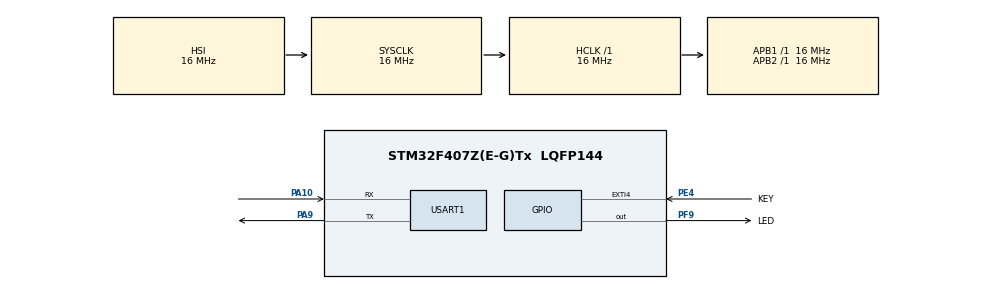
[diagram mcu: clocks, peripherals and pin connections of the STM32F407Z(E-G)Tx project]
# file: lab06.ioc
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Mcu.Family=STM32F4
Mcu.Name=STM32F407Z(E-G)Tx
Mcu.Package=LQFP144
NVIC.EXTI4_IRQn=true\:0\:0\:false\:true\:true\:2\:true\:true
NVIC.PriorityGroup=NVIC_PRIORITYGROUP_4
NVIC.USART1_IRQn=true\:0\:0\:false\:true\:true\:1\:true\:true
PA10.Mode=Asynchronous
PA10.Signal=USART1_RX
PA9.Mode=Asynchronous
PA9.Signal=USART1_TX
PE4.GPIO_Label=KEY
PE4.GPIO_ModeDefaultEXTI=GPIO_MODE_IT_FALLING
PE4.GPIO_PuPd=GPIO_PULLUP
PE4.Signal=GPXTI4
PF9.GPIO_Label=LED
PF9.Signal=GPIO_Output
ProjectManager.HeapSize=0x200
ProjectManager.StackSize=0x400
ProjectManager.TargetToolchain=STM32CubeIDE
RCC.AHBFreq_Value=16000000
RCC.APB1Freq_Value=16000000
RCC.APB2Freq_Value=16000000
RCC.CortexFreq_Value=16000000
RCC.HSE_VALUE=25000000
RCC.HSI_VALUE=16000000
RCC.LSE_VALUE=32768
RCC.SYSCLKFreq_VALUE=16000000
RCC.VCOOutputFreq_Value=192000000
USART1.VirtualMode=VM_ASYNC
board=custom

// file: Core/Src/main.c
/* USER CODE BEGIN Header */
/**
  ******************************************************************************
  * @file           : main.c
  * @brief          : Main program body
  ******************************************************************************
  * @attention
  *
  * <h2><center>&copy; Copyright (c) 2022 STMicroelectronics.
  * All rights reserved.</center></h2>
  *
  * This software component is licensed by ST under BSD 3-Clause license,
  * the "License"; You may not use this file except in compliance with the
  * License. You may obtain a copy of the License at:
  *                        opensource.org/licenses/BSD-3-Clause
  *
  ******************************************************************************
  */
/* USER CODE END Header */
#include "main.h"

/* USER CODE BEGIN Includes */
#include <stdio.h>
/* USER CODE END Includes */

UART_HandleTypeDef huart1;

/* USER CODE BEGIN PV */
char buffer[36];
uint32_t counter;
/* USER CODE END PV */

void SystemClock_Config(void);
static void MX_GPIO_Init(void);
static void MX_USART1_UART_Init(void);
static void MX_NVIC_Init(void);

int main(void)
{

  /* MCU Configuration--------------------------------------------------------*/

  /* Reset of all peripherals, Initializes the Flash interface and the Systick. */
  HAL_Init();

  /* Configure the system clock */
  SystemClock_Config();

  /* Initialize all configured peripherals */
  MX_GPIO_Init();
  MX_USART1_UART_Init();

  /* Initialize interrupts */
  MX_NVIC_Init();

  /* Infinite loop */
  /* USER CODE BEGIN WHILE */
  while (1)
  {
	  sprintf(buffer, "Hello Embedded! Counter: %lu\n\r", counter);
	  HAL_UART_Transmit_IT(&huart1, (uint8_t*)buffer, sizeof(buffer));
	  counter++;
	  HAL_Delay(500);
    /* USER CODE END WHILE */

  }
}

void SystemClock_Config(void)
{
  RCC_OscInitTypeDef RCC_OscInitStruct = {0};
  RCC_ClkInitTypeDef RCC_ClkInitStruct = {0};

  /** Configure the main internal regulator output voltage
  */
  __HAL_RCC_PWR_CLK_ENABLE();
  __HAL_PWR_VOLTAGESCALING_CONFIG(PWR_REGULATOR_VOLTAGE_SCALE1);
  /** Initializes the RCC Oscillators according to the specified parameters
  * in the RCC_OscInitTypeDef structure.
  */
  RCC_OscInitStruct.OscillatorType = RCC_OSCILLATORTYPE_HSI;
  RCC_OscInitStruct.HSIState = RCC_HSI_ON;
  RCC_OscInitStruct.HSICalibrationValue = RCC_HSICALIBRATION_DEFAULT;
  RCC_OscInitStruct.PLL.PLLState = RCC_PLL_NONE;
  if (HAL_RCC_OscConfig(&RCC_OscInitStruct) != HAL_OK)
  {
    Error_Handler();
  }
  /** Initializes the CPU, AHB and APB buses clocks
  */
  RCC_ClkInitStruct.ClockType = RCC_CLOCKTYPE_HCLK|RCC_CLOCKTYPE_SYSCLK
                              |RCC_CLOCKTYPE_PCLK1|RCC_CLOCKTYPE_PCLK2;
  RCC_ClkInitStruct.SYSCLKSource = RCC_SYSCLKSOURCE_HSI;
  RCC_ClkInitStruct.AHBCLKDivider = RCC_SYSCLK_DIV1;
  RCC_ClkInitStruct.APB1CLKDivider = RCC_HCLK_DIV1;
  RCC_ClkInitStruct.APB2CLKDivider = RCC_HCLK_DIV1;

  if (HAL_RCC_ClockConfig(&RCC_ClkInitStruct, FLASH_LATENCY_0) != HAL_OK)
  {
    Error_Handler();
  }
}

/**
  * @brief NVIC Configuration.
  * @retval None
  */
static void MX_NVIC_Init(void)
{
  /* USART1_IRQn interrupt configuration */
  HAL_NVIC_SetPriority(USART1_IRQn, 0, 0);
  HAL_NVIC_EnableIRQ(USART1_IRQn);
  /* EXTI4_IRQn interrupt configuration */
  HAL_NVIC_SetPriority(EXTI4_IRQn, 0, 0);
  HAL_NVIC_EnableIRQ(EXTI4_IRQn);
}

static void MX_USART1_UART_Init(void)
{

  huart1.Instance = USART1;
  huart1.Init.BaudRate = 115200;
  huart1.Init.WordLength = UART_WORDLENGTH_8B;
  huart1.Init.StopBits = UART_STOPBITS_1;
  huart1.Init.Parity = UART_PARITY_NONE;
  huart1.Init.Mode = UART_MODE_TX_RX;
  huart1.Init.HwFlowCtl = UART_HWCONTROL_NONE;
  huart1.Init.OverSampling = UART_OVERSAMPLING_16;
  if (HAL_UART_Init(&huart1) != HAL_OK)
  {
    Error_Handler();
  }

}

static void MX_GPIO_Init(void)
{
  GPIO_InitTypeDef GPIO_InitStruct = {0};

  /* GPIO Ports Clock Enable */
  __HAL_RCC_GPIOE_CLK_ENABLE();
  __HAL_RCC_GPIOF_CLK_ENABLE();
  __HAL_RCC_GPIOA_CLK_ENABLE();

  /*Configure GPIO pin Output Level */
  HAL_GPIO_WritePin(LED_GPIO_Port, LED_Pin, GPIO_PIN_RESET);

  /*Configure GPIO pin : KEY_Pin */
  GPIO_InitStruct.Pin = KEY_Pin;
  GPIO_InitStruct.Mode = GPIO_MODE_IT_FALLING;
  GPIO_InitStruct.Pull = GPIO_PULLUP;
  HAL_GPIO_Init(KEY_GPIO_Port, &GPIO_InitStruct);

  /*Configure GPIO pin : LED_Pin */
  GPIO_InitStruct.Pin = LED_Pin;
  GPIO_InitStruct.Mode = GPIO_MODE_OUTPUT_PP;
  GPIO_InitStruct.Pull = GPIO_NOPULL;
  GPIO_InitStruct.Speed = GPIO_SPEED_FREQ_LOW;
  HAL_GPIO_Init(LED_GPIO_Port, &GPIO_InitStruct);

}

/* USER CODE BEGIN 4 */
void HAL_UART_TxCpltCallback(UART_HandleTypeDef *huart) {
	if (huart->Instance == USART1) {
		HAL_GPIO_TogglePin(LED_GPIO_Port, LED_Pin);
	}
}

void HAL_GPIO_EXTI_Callback(uint16_t GPIO_Pin)
{
	if (GPIO_Pin == KEY_Pin) {
		counter = 0;
	}
}
/* USER CODE END 4 */

void Error_Handler(void)
{
  __disable_irq();
  while (1)
  {
  }
}

/************************ (C) COPYRIGHT STMicroelectronics *****END OF FILE****/
